# SAMA7D65D4GN8 register map
Vendor: Microchip Technology; Series: SAMA7D6; File version: 0
Registers are 32-bit, read-write, reset 0x0 unless marked. A register's access mark holds for its fields unless they carry their own. Offsets are from the block's base; [hi:lo] are bit positions; lines under a group give offsets from that group; {n}, {i} and the like mark numbered series; 'fields as' and 'values as' point back to an identical list.

## LCDC — LCD Controller
Base 0xE1400000
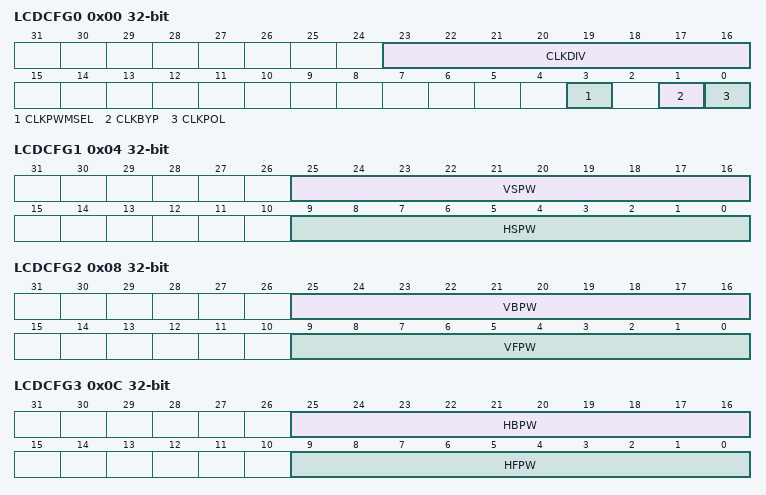
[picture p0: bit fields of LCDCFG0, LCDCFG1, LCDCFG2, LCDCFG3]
0x00 LCDCFG0 — Configuration Register 0
  [23:16] CLKDIV — LCDC Clock Divider
  [3] CLKPWMSEL — LCDC PWM Clock Source Selection
    0=The slow clock is selected and feeds the PWM module; 1=The peripheral clock (MCK) is selected and feeds the PWM module
  [1] CLKBYP — LCDC Pixel Clock Divider Bypass
    0=Pixel clock divider is not bypassed. LCDC_PCK is defined with CLKDIV parameter.; 1=Pixel clock divider is bypassed. LCDC_PCK = GCLK clock
  [0] CLKPOL — LCDC Clock Polarity
    0=Data/Control signals are launched on the rising edge of the pixel clock; 1=Data/Control signals are launched on the falling edge of the pixel clock
0x04 LCDCFG1 — Configuration Register 1
  [25:16] VSPW — Vertical Synchronization Pulse Width
  [9:0] HSPW — Horizontal Synchronization Pulse Width
0x08 LCDCFG2 — Configuration Register 2
  [25:16] VBPW — Vertical Back Porch Width
  [9:0] VFPW — Vertical Front Porch Width
0x0C LCDCFG3 — Configuration Register 3
  [25:16] HBPW — Horizontal Back Porch Width
  [9:0] HFPW — Horizontal Front Porch Width
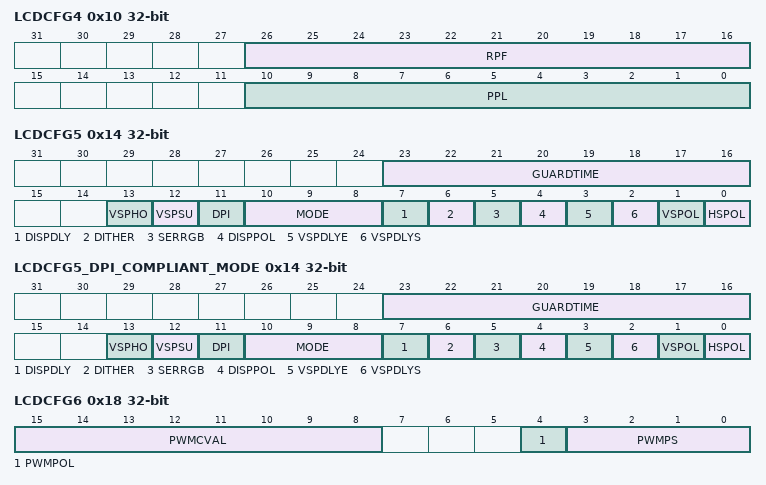
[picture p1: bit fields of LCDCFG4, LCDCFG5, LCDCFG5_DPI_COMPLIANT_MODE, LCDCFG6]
0x10 LCDCFG4 — Configuration Register 4
  [26:16] RPF — Number of Active Row Per Frame
  [10:0] PPL — Number of Pixels Per Line
0x14 LCDCFG5 — Configuration Register 5
  [23:16] GUARDTIME — LCD Display Guard Time
  [13] VSPHO — LCDC Vertical Synchronization Pulse Hold Configuration
    0=The vertical synchronization pulse is asserted synchronously with horizontal pulse edge; 1=The vertical synchronization pulse is held active one pixel clock cycle after the horizontal pulse
  [12] VSPSU — LCDC Vertical Synchronization Pulse Setup Configuration
    0=The vertical synchronization pulse is asserted synchronously with horizontal pulse edge; 1=The vertical synchronization pulse is asserted one pixel clock cycle before the horizontal pulse
  [11] DPI — Display Pixel Interface Compatible Mode
    0=Legacy pixel mapping; 1=Activates the DPI compliant pixel stream. See field MODE: LCDC Output Mode
  [10:8] MODE — LCDC Output Mode
    0=OUTPUT_12BPP (LCD Output mode is set to 12 bits per pixel); 1=OUTPUT_16BPP (LCD Output mode is set to 16 bits per pixel); 2=OUTPUT_18BPP (LCD Output mode is set to 18 bits per pixel); 3=OUTPUT_24BPP (LCD Output mode is set to 24 bits per pixel)
  [7] DISPDLY — LCDC Display Power Signal Synchronization
    0=The LCDC_DISP signal is asserted synchronously with the second active edge of the horizontal pulse; 1=The LCDC_DISP signal is asserted asynchronously with both edges of the horizontal pulse
  [6] DITHER — LCDC Dithering
    0=Dithering logical unit is disabled; 1=Dithering logical unit is activated
  [5] SERRGB — Serial RGB Mode (See Figure 7-29)
    0=Serial RGB mode is disabled; 1=Serial RGB mode is enabled
  [4] DISPPOL — Display Signal Polarity
    0=Active high; 1=Active low
  [3] VSPDLYE — Vertical Synchronization Pulse End
    0=The second active edge of the vertical synchronization pulse is synchronous with the second edge of the horizontal pulse; 1=The second active edge of the vertical synchronization pulse is synchronous with the first edge of the horizontal pulse
  [2] VSPDLYS — Vertical Synchronization Pulse Start
    0=The first active edge of the vertical synchronization pulse is synchronous with the second edge of the horizontal pulse; 1=The first active edge of the vertical synchronization pulse is synchronous with the first edge of the horizontal pulse
  [1] VSPOL — Vertical Synchronization Pulse Polarity
    0=Active high; 1=Active low
  [0] HSPOL — Horizontal Synchronization Pulse Polarity
    0=Active high; 1=Active low
0x14 LCDCFG5_DPI_COMPLIANT_MODE (alternate view of LCDCFG5) — Configuration Register 5
  [23:16] GUARDTIME — LCD Display Guard Time
  [13] VSPHO — LCDC Vertical Synchronization Pulse Hold Configuration
    values as LCDCFG5.VSPHO
  [12] VSPSU — LCDC Vertical Synchronization Pulse Setup Configuration
    values as LCDCFG5.VSPSU
  [11] DPI — Display Pixel Interface Compatible Mode
    values as LCDCFG5.DPI
  [10:8] MODE — LCDC Output Mode
    0=OUTPUT_DPI_16BPPCFG1 (LCD Output mode is set to 16 bits per pixel Configuration 1); 1=OUTPUT_DPI_16BPPCFG2 (LCD Output mode is set to 16 bits per pixel Configuration 2); 2=OUTPUT_DPI_16BPPCFG3 (LCD Output mode is set to 16 bits per pixel Configuration 3); 3=OUTPUT_DPI_18BPPCFG1 (LCD Output mode is set to 18 bits per pixel Configuration 1); 4=OUTPUT_DPI_18BPPCFG2 (LCD Output mode is set to 18 bits per pixel Configuration 2); 5=OUTPUT_DPI_24BPP (LCD Output mode is set to 24 bits per pixel)
  [7] DISPDLY — LCDC Display Power Signal Synchronization
    values as LCDCFG5.DISPDLY
  [6] DITHER — LCDC Dithering
    values as LCDCFG5.DITHER
  [5] SERRGB — Serial RGB Mode (See Figure 7-29)
    0=Serial RGB mode is disabled; 1=Serial RGB mode is enabled
  [4] DISPPOL — Display Signal Polarity
    0=Active high; 1=Active low
  [3] VSPDLYE — Vertical Synchronization Pulse End
    values as LCDCFG5.VSPDLYE
  [2] VSPDLYS — Vertical Synchronization Pulse Start
    values as LCDCFG5.VSPDLYS
  [1] VSPOL — Vertical Synchronization Pulse Polarity
    0=Active high; 1=Active low
  [0] HSPOL — Horizontal Synchronization Pulse Polarity
    0=Active high; 1=Active low
0x18 LCDCFG6 — Configuration Register 6
  [15:8] PWMCVAL — LCDC PWM Compare Value
  [4] PWMPOL — LCDC PWM Signal Polarity
    0=The output pulses are low level; 1=The output pulses are high level (the output is high whenever the value in the counter is less than the value PWMCVAL)
  [3:0] PWMPS — PWM Clock Prescaler
    0=DIV_1 (The counter advances at a rate of fCOUNTER = fPWM_SELECTED_CLOCK); 1=DIV_2 (The counter advances at a rate of fCOUNTER = fPWM_SELECTED_CLOCK/2); 2=DIV_4 (The counter advances at a rate of fCOUNTER = fPWM_SELECTED_CLOCK/4); 3=DIV_8 (The counter advances at a rate of fCOUNTER = fPWM_SELECTED_CLOCK/8); 4=DIV_16 (The counter advances at a rate of fCOUNTER = fPWM_SELECTED_CLOCK/16); 5=DIV_32 (The counter advances at a of rate fCOUNTER = fPWM_SELECTED_CLOCK/32); 6=DIV_64 (The counter advances at a of rate fCOUNTER = fPWM_SELECTED_CLOCK/64); 7=DIV_128 (The counter advances at a of rate fCOUNTER = fPWM_SELECTED_CLOCK/128); 8=DIV_256 (The counter advances at a of rate fCOUNTER = fPWM_SELECTED_CLOCK/256); 9=DIV_512 (The counter advances at a of rate fCOUNTER = fPWM_SELECTED_CLOCK/512); 10=DIV_1024 (The counter advances at a of rate fCOUNTER = fPWM_SELECTED_CLOCK/1024); 11=DIV_2048 (The counter advances at a of rate fCOUNTER = fPWM_SELECTED_CLOCK/2048); 12=DIV_4096 (The counter advances at a of rate fCOUNTER = fPWM_SELECTED_CLOCK/4096); 13=DIV_8192 (The counter advances at a of rate fCOUNTER = fPWM_SELECTED_CLOCK/8192); 14=DIV_16384 (The counter advances at a of rate fCOUNTER = fPWM_SELECTED_CLOCK/16384); 15=DIV_32768 (The counter advances at a of rate fCOUNTER = fPWM_SELECTED_CLOCK/32768)
0x1C LCDCFG7 — Configuration Register 7
  [10:0] ROW — Row Identifier For Row Interrupt Signal
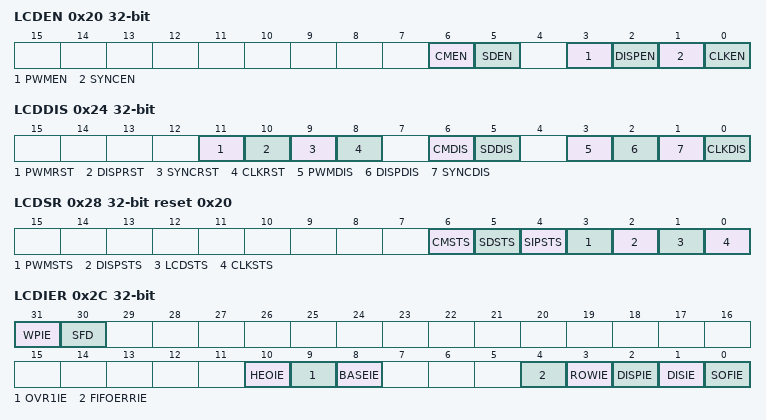
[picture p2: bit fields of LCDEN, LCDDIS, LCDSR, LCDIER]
0x20 LCDEN wo — Enable Register
  [6] CMEN — Color Mode Signal Enable
    0=No effect; 1=Sets the color mode signal (lcd_cm) to one. If a rising edge is generated, signals the MIPI DSI host to send a 'Color Mode On' command to the LCD screen when the MIPI output interface is selected.
  [5] SDEN — Shutdown Signal Enable
    0=No effect; 1=Sets the shutdown signal (lcd_sd) to zero (turns on the display)
  [3] PWMEN — LCDC Pulse Width Modulation Enable
    0=No effect; 1=PWM is enabled
  [2] DISPEN — LCDC DISP Signal Enable
    0=No effect; 1=LCDC_DISP signal is generated
  [1] SYNCEN — LCDC Horizontal and Vertical Synchronization Enable
    0=No effect; 1=Both horizontal and vertical synchronization (LCD_VSYNC and LCD_HSYNC) signals are generated
  [0] CLKEN — LCDC Pixel Clock Enable
    0=No effect; 1=Pixel clock logical unit is activated
0x24 LCDDIS wo — Disable Register
  [11] PWMRST — LCDC PWM Reset
    0=No effect; 1=Resets the PWM module immediately. The duty cycle may be violated.
  [10] DISPRST — LCDC DISP Signal Reset
    0=No effect; 1=Resets the DISP signal immediately
  [9] SYNCRST — LCDC Horizontal and Vertical Synchronization Reset
    0=No effect; 1=Resets the timing engine immediately. The horizontal and vertical pulse widths are both violated.
  [8] CLKRST — LCDC Clock Reset
    0=No effect; 1=Resets the pixel clock generator module immediately. The pixel clock duty cycle may be violated.
  [6] CMDIS — Color Mode Signal Disable
    0=No effect; 1=Sets the color mode signa (lcd_cm) to zero. If a falling edge is generated, signals the MIPI DSI host to send a 'Color Mode Off' command to the LCD screen when the MIPI output interface is selected).
  [5] SDDIS — Shutdown Signal Disable
    0=No effect; 1=Sets the shutdown signal (lcd_sd) to one (turns off the display)
  [3] PWMDIS — LCDC Pulse Width Modulation Disable
    0=No effect; 1=Disables the pulse width modulation signal after the end of the frame
  [2] DISPDIS — LCDC DISP Signal Disable
    0=No effect; 1=Disables the DISP signal after the end of the frame
  [1] SYNCDIS — LCDC Horizontal and Vertical Synchronization Disable
    0=No effect; 1=Disables the synchronization signals after the end of the frame
  [0] CLKDIS — LCDC Pixel Clock Disable
    0=No effect; 1=Disables the pixel clock after the end of the frame
0x28 LCDSR ro reset 0x20 — Status Register
  [6] CMSTS — Color Mode Signal Status
    0=Color mode signal output is zero; 1=Color mode signal output is one
  [5] SDSTS — Shutdown Signal Status
    0=Shutdown signal output is zero; 1=Shutdown signal output is one
  [4] SIPSTS — Synchronization In Progress
    0=Clock domain synchronization is terminated; 1=Synchronization is in progress. Access to the registers LCDC_LCDCCFG[0..7], LCDC_LCDEN and LCDC_LCDDIS has no effect.
  [3] PWMSTS — LCDC PWM Signal Status
    0=PWM is disabled; 1=PWM signal is activated
  [2] DISPSTS — LCDC DISP Signal Status
    0=DISP is disabled; 1=DISP signal is activated
  [1] LCDSTS — LCDC Synchronization Status
    0=Timing engine is disabled; 1=Timing engine is running
  [0] CLKSTS — Clock Status
    0=Pixel clock is disabled; 1=Pixel clock is running
0x2C LCDIER wo — Interrupt Enable Register
  [31] WPIE — Write Protection Interrupt Enable
  [30] SFD — Safety Fault Detection Interrupt Enable
  [10] HEOIE — High-End Overlay Interrupt Enable
  [9] OVR1IE — Overlay 1 Interrupt Enable
  [8] BASEIE — Base Layer Interrupt Enable
  [4] FIFOERRIE — Output FIFO Error Interrupt Enable
  [3] ROWIE — Row Interrupt Enable
  [2] DISPIE — Power-up/Power-down Sequence Terminated Interrupt Enable
  [1] DISIE — LCD Disable Interrupt Enable
  [0] SOFIE — Start of Frame Interrupt Enable
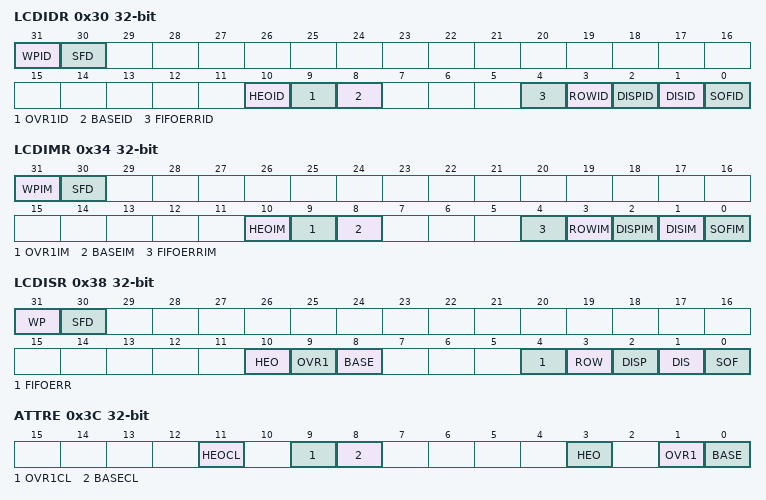
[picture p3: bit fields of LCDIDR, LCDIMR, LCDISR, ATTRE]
0x30 LCDIDR wo — Interrupt Disable Register
  [31] WPID — Write Protection Interrupt Disable
  [30] SFD — Safety Fault Detection Interrupt Disable
  [10] HEOID — High-End Overlay Interrupt Disable
  [9] OVR1ID — Overlay 1 Interrupt Disable
  [8] BASEID — Base Layer Interrupt Disable
  [4] FIFOERRID — Output FIFO Error Interrupt Disable
  [3] ROWID — Row Interrupt Disable
  [2] DISPID — Power-up/Power-down Sequence Terminated Interrupt Disable
  [1] DISID — LCD Disable Interrupt Disable
  [0] SOFID — Start of Frame Interrupt Disable
0x34 LCDIMR ro — Interrupt Mask Register
  [31] WPIM — Write Protection Interrupt Mask
  [30] SFD — Safety Fault Detection Interrupt Mask
  [10] HEOIM — High-End Overlay Interrupt Mask
  [9] OVR1IM — Overlay 1 Interrupt Mask
  [8] BASEIM — Base Layer Interrupt Mask
  [4] FIFOERRIM — Output FIFO Error Interrupt Mask
  [3] ROWIM — Row Interrupt Mask
  [2] DISPIM — Power-up/Power-down Sequence Terminated Interrupt Mask
  [1] DISIM — LCD Disable Interrupt Mask
  [0] SOFIM — Start of Frame Interrupt Mask
0x38 LCDISR ro — Interrupt Status Register
  [31] WP — Write Protection Interrupt Status
    0=No Write Protection interrupt detected since last read of LCDC_LCDISR; 1=Indicates that Write Protection error has been detected. This flag is reset after a read operation.
  [30] SFD — Safety Fault Detection Interrupt Status
    0=No detection since last read of LCDC_LCDISR; 1=Indicates that a fault has been detected in the fault detection mechanism. This flag is reset after a read operation.
  [10] HEO — High-End Overlay Raw Interrupt Status
    0=No High-End layer interrupt detected since last read of LCDC_HEOISR; 1=Indicates that a High-End layer interrupt is pending. This flag is reset as soon as the LCDC_HEOISR is read.
  [9] OVR1 — Overlay 1 Raw Interrupt Status
    0=No Overlay 1 layer interrupt detected since last read of LCDC_OVR1ISR; 1=Indicates that an Overlay 1 layer interrupt is pending. This flag is reset as soon as the LCDC_OVR1ISR is read.
  [8] BASE — Base Layer Raw Interrupt Status
    0=No base layer interrupt detected since last read of LCDC_BASEISR; 1=Indicates that a base layer interrupt is pending. This flag is reset as soon as the LCDC_BASEISR is read.
  [4] FIFOERR — Output FIFO Error
    0=No underflow has occurred in the output FIFO since last read of LCDC_LCDISR; 1=Indicates that an underflow has occurred in the output FIFO. This flag is reset after a read operation.
  [3] ROW — Row Interrupt Status
    0=No detection since last read of the LCDC_LCDCISR; 1=Indicates that a row event has been detected. This flag is reset after a read operation.
  [2] DISP — Power-up/Power-down Sequence Terminated Interrupt Status
    0=Power-up sequence or power-down sequence has not yet terminated; 1=Indicates the power-up sequence or power-down sequence has terminated. This flag is reset after a read operation.
  [1] DIS — LCD Disable Interrupt Status
    0=Horizontal and vertical timing generator has not yet been disabled; 1=Indicates that the horizontal and vertical timing generator has been disabled. This flag is reset after a read operation.
  [0] SOF — Start of Frame Interrupt Status
    0=No detection since last read of LCDC_LCDISR; 1=Indicates that a start of frame event has been detected. This flag is reset after a read operation.
0x3C ATTRE wo — Attribute Enable Register
  [11] HEOCL — High-End Overlay Update Color LUT
    0=No effect; 1=DMA update request for the HEO layer CLUT content
  [9] OVR1CL — Overlay 1 Update Color LUT
    0=No effect; 1=DMA update request for the OVR1 layer CLUT content
  [8] BASECL — Base Layer Update Color LUT
    0=No effect; 1=DMA update request for the base layer CLUT content
  [3] HEO — High-End Overlay Update Attribute
    0=No effect; 1=Updates the HEO window attribute
  [1] OVR1 — Overlay 1 Update Attribute
    0=No effect; 1=Updates the OVR1 window attribute
  [0] BASE — Base Layer Update Attribute
    0=No effect; 1=Updates the base window attributes
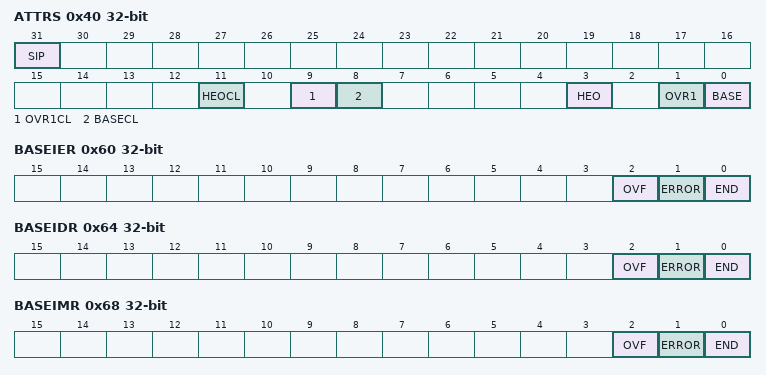
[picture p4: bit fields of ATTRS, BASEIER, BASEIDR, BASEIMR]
0x40 ATTRS ro — Attribute Status Register
  [31] SIP — Synchronization In Progress
    0=Clock domain synchronization is terminated; 1=Synchronization is in progress. Access to LCDC_ATTRE has no effect.
  [11] HEOCL — High-End Overlay Color Table Status
    0=No effect; 1=Indicates that an update request is pending for the High-end Overlay CLUT
  [9] OVR1CL — Overlay 1 Color Table Status
    0=No effect; 1=Indicates that an update request is pending for the Overlay 1 CLUT
  [8] BASECL — Base Layer Color Table Status
    0=No effect; 1=Indicates that an update request is pending for the base CLUT
  [3] HEO — High-End Overlay Update Status
    0=No effect; 1=Indicates that an update request is pending for High-end Overlay
  [1] OVR1 — Overlay 1 Update Status
    0=No effect; 1=Indicates that an update request is pending for the Overlay 1 layer
  [0] BASE — Base Layer Update Status
    0=No effect; 1=Indicates that an update request is pending for the base layer
0x60 BASEIER wo — Base Layer Interrupt Enable Register
  [2] OVF — Overflow Interrupt Enable
  [1] ERROR — Transfer Error Detected Interrupt Enable
  [0] END — End of Frame DMA Transfer Interrupt Enable
0x64 BASEIDR wo — Base Layer Interrupt Disable Register
  [2] OVF — Overflow Interrupt Disable
  [1] ERROR — Transfer Error Interrupt Disable
  [0] END — End of Frame DMA Transfer Interrupt Disable
0x68 BASEIMR ro — Base Layer Interrupt Mask Register
  [2] OVF — Overflow Interrupt Mask
  [1] ERROR — Transfer Error Interrupt Mask
  [0] END — End of Frame DMA Transfer Interrupt Mask
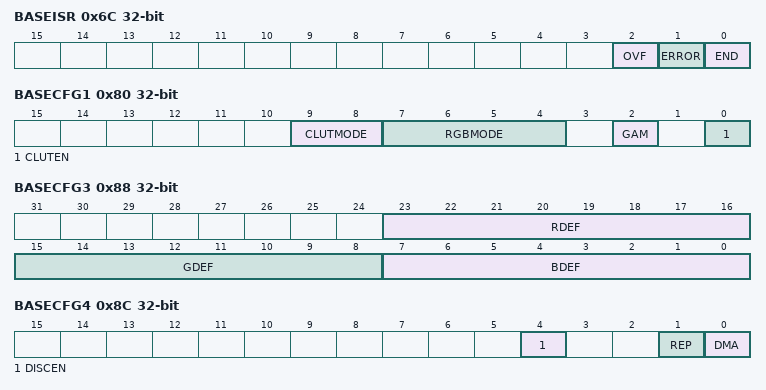
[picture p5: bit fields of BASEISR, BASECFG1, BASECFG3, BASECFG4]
0x6C BASEISR ro — Base Layer Interrupt Status Register
  [2] OVF — Overflow Detected
    0=No overflow occurred since last read of LCDC_BASEISR; 1=An overflow occurred, at least one DMA transfer is still running at the End Of Frame. This flag is reset after a read operation.
  [1] ERROR — Transfer Error Detected
    0=No system bus error has been detected since the last read of LCDC_BASEISR; 1=A system bus error has been detected. This flag is reset after a read operation.
  [0] END — End of Frame DMA Transfer
    0=No end of frame DMA transfer has been detected since last read of LCDC_BASEISR; 1=End of transfer has been detected. This flag is reset after a read operation.
0x70 BASEEN — Base Layer Enable Register
  [0] ENABLE — Base Layer Enable
    0=The layer is disabled; 1=The layer is enabled
0x74 BASECLA — Base Layer Color Table Address Register
  [31:3] CLA — Base Layer CLUT Address
0x78 BASEFBA — Base Layer Frame Buffer Address Register
  [31:2] FBA — Frame Buffer Address
0x7C BASECFG0 — Base Layer Configuration Register 0
  [6:4] BLEN — System Bus Burst Length
    0=INCR1 (System bus access is started as soon as there is enough space in the FIFO to store one data.); 1=INCR4 (System bus access is started as soon as there is enough space in the FIFO to store a total amount of 4 data. A system bus INCR4 Burst is used by default. INCR1 is used for bursts less than 4.); 2=INCR8 (System bus access is started as soon as there is enough space in the FIFO to store a total amount of 8 data. A system bus INCR8 Burst is used by default. INCR4 bursts are used for bursts of 4 beats.INCR1 is used for bursts less than 4.); 3=INCR16 (System bus access is started as soon as there is enough space in the FIFO to store a total amount of 16 data. A system bus INCR16 Burst is used by default. INCR8 and INCR4 bursts are respectively used for bursts of 8 and 4 beats.INCR1 is used for bursts less than 4.); 4=INCR32 (System bus access is started as soon as there is enough space in the FIFO to store a total amount of 32 data. A system bus INCR32 Burst is used by default. INCR16, INCR8 and INCR4 bursts are respectively used for bursts of 16, 8 and 4 beats. INCR1 is used for bursts less than 4.)
0x80 BASECFG1 — Base Layer Configuration Register 1
  [9:8] CLUTMODE — CLUT Mode Input Selection
    0=CLUT_1BPP (CLUT mode set to 1 bit per pixel); 1=CLUT_2BPP (CLUT mode set to 2 bits per pixel); 2=CLUT_4BPP (CLUT mode set to 4 bits per pixel); 3=CLUT_8BPP (CLUT mode set to 8 bits per pixel)
  [7:4] RGBMODE — RGB Mode Input Selection
    0=12BPP_RGB_444; 1=16BPP_ARGB_4444; 2=16BPP_RGBA_4444; 3=16BPP_RGB_565; 4=16BPP_ARGB_1555; 5=18BPP_RGB_666; 6=18BPP_RGB_666PACKED; 7=19BPP_ARGB_1666; 8=19BPP_ARGB_PACKED (19 bpp ARGB 1666 PACKED); 9=24BPP_RGB_888; 10=24BPP_RGB_888_PACKED; 11=25BPP_ARGB_1888; 12=32BPP_ARGB_8888; 13=32BPP_RGBA_8888
  [2] GAM — Gamma Correction
    0=Gamma correction is disabled; 1=Gamma correction is activated
  [0] CLUTEN — CLUT Mode Enable
    0=RGB mode is selected; 1=CLUT mode is selected
0x84 BASECFG2 — Base Layer Configuration Register 2
  [31:0] XSTRIDE — Horizontal Stride
0x88 BASECFG3 — Base Layer Configuration Register 3
  [23:16] RDEF — Red Default
  [15:8] GDEF — Green Default
  [7:0] BDEF — Blue Default
0x8C BASECFG4 — Base Layer Configuration Register 4
  [4] DISCEN — Discard Area Enable
    0=The whole frame is retrieved from memory; 1=The DMA channel discards the area located at screen coordinates {DISCXPOS, DISCYPOS}
  [1] REP — Use Replication Logic to Expand RGB Color to 24 Bits
    0=When the selected pixel depth is less than 24 bpp, the pixel is shifted and LSBs are set to 0; 1=When the selected pixel depth is less than 24 bpp, the pixel is shifted and the LSB replicates the MSB
  [0] DMA — Use DMA Data Path
    0=The default color is used on the base layer; 1=The DMA channel retrieves the pixel stream from the memory
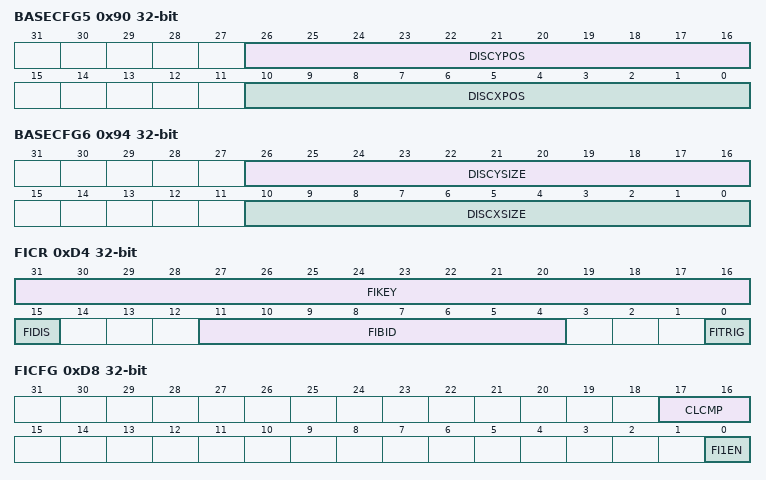
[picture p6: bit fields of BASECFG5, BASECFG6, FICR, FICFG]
0x90 BASECFG5 — Base Layer Configuration Register 5
  [26:16] DISCYPOS — Discard Area Vertical Coordinate
  [10:0] DISCXPOS — Discard Area Horizontal Coordinate
0x94 BASECFG6 — Base Layer Configuration Register 6
  [26:16] DISCYSIZE — Discard Area Vertical Size
  [10:0] DISCXSIZE — Discard Area Horizontal Size
0xD4 FICR — Fault Injection Control Register
  [31:16] FIKEY — Write Protection Key Password
    0x4C43=PASSWD (Writing any other value in this field aborts the write operation of the FITRIG, FIBID bits. Always reads as 0.)
  [15] FIDIS — Fault Injection Control Register Disable
    0=NO_EFFECT; 1=ACTIVE (Locks the write access to LCDC_FICR until the next system reset.)
  [11:4] FIBID — Fault Injection Block Index
  [0] FITRIG — Fault Injection Trigger
    0=No Fault is injected; 1=Fault is injected once
0xD8 FICFG — Fault Injection Configuration Register
  [17:16] CLCMP — CLUT Ram Component Index
    0=Blue Component; 1=Green Component; 2=Red Component; 3=Alpha Component
  [0] FI1EN — Fault Injection 1 Enable
    0=First fault injection is disabled; 1=First fault injection is enabled
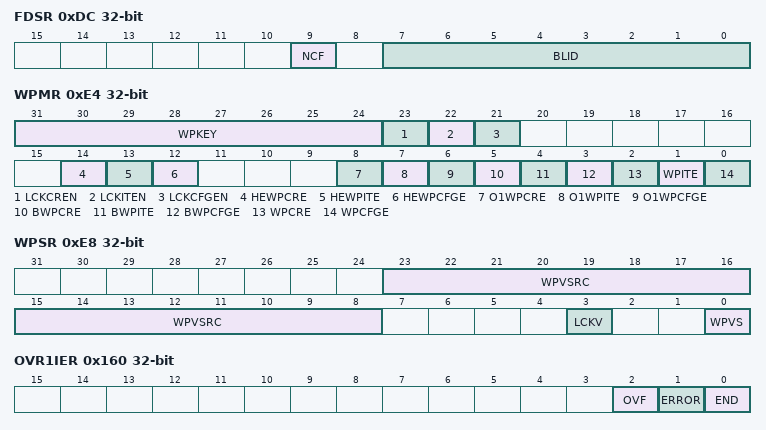
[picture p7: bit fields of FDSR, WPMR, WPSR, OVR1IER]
0xDC FDSR ro — Fault Detection Status Register
  [9] NCF — Non-Corrected Fault Status
    0=No non-correctable fault has been detected since the last read of LCDC_FDSR; 1=A non-correctable fault has been detected. This flag is reset after a read operation.
  [7:0] BLID — Block Index
0xE4 WPMR — Write Protection Mode Register
  [31:24] WPKEY — Write Protection Key Password
    88=PASSWD (Writing any other value in this field aborts the write operation of the WPCFGE, WPITE, WPCRE bits. Always reads as 0.)
  [23] LCKCREN — Write Protection Lock Enable for Control Register
    0=No effect; 1=Locks the write access to the WPCRE bit until the next system reset. WPCRE must be set in the same access to per-form the action.
  [22] LCKITEN — Write Protection Lock Enable for Interrupt Register
    0=No effect; 1=Locks the write access to the WPITE bit until the next system reset. WPITE must be set in the same access to per-form the action.
  [21] LCKCFGEN — Write Protection Lock Enable for Configuration Register
    0=No effect; 1=Locks the write access to the WPCFEN bit until the next system reset. WPCFEN must be set in the same access to per-form the action.
  [14] HEWPCRE — High-End Overlay Write Protection Control Registers Enable
    0=Disables the write protection of High-End Overlay Control registers if WPKEY corresponds to 0x58 ('X' in ASCII); 1=Enables the write protection of High-End Overlay Control registers if WPKEY corresponds to 0x58 ('X' in ASCII)
  [13] HEWPITE — High-End Overlay Write Protection Interrupt Registers Enable
    0=Disables the write protection of High-End Overlay Interrupt Enable/Disable registers if WPKEY corresponds to 0x58 ('X' in ASCII); 1=Enables the write protection of High-End Overlay Interrupt Enable/Disable registers if WPKEY corresponds to 0x58 ('X' in ASCII)
  [12] HEWPCFGE — High-End Overlay Write Protection Configuration Registers Enable
    0=Disables the write protection of High-End Overlay Configuration registers if WPKEY corresponds to 0x58 ('X' in ASCII); 1=Enables the write protection of High-End Overlay Configuration registers if WPKEY corresponds to 0x58 ('X' in ASCII)
  [8] O1WPCRE — Overlay 1 Write Protection Control Registers Enable
    0=Disables the write protection of Overlay 1 Control registers if WPKEY corresponds to 0x58 ('X' in ASCII); 1=Enables the write protection of Overlay 1 Control registers if WPKEY corresponds to 0x58 ('X' in ASCII)
  [7] O1WPITE — Overlay 1 Write Protection Interrupt Registers Enable
    0=Disables the write protection of Overlay 1 Interrupt Enable/Disable registers if WPKEY corresponds to 0x58 ('X' in ASCII); 1=Enables the write protection of Overlay 1 Interrupt Enable/Disable registers if WPKEY corresponds to 0x58 ('X' in ASCII)
  [6] O1WPCFGE — Overlay 1 Write Protection Configuration Registers Enable
    0=Disables the write protection of Overlay 1 Configuration registers if WPKEY corresponds to 0x58 ('X' in ASCII); 1=Enables the write protection of Overlay 1 Configuration registers if WPKEY corresponds to 0x58 ('X' in ASCII)
  [5] BWPCRE — Base Layer Write Protection Control Registers Enable
    0=Disables the write protection of base layer Control registers if WPKEY corresponds to 0x58 ('X' in ASCII); 1=Enables the write protection of base layer Control registers if WPKEY corresponds to 0x58 ('X' in ASCII)
  [4] BWPITE — Base Layer Write Protection Interrupt Registers Enable
    0=Disables the write protection of base layer Interrupt Enable/Disable registers if WPKEY corresponds to 0x58 ('X' in ASCII); 1=Enables the write protection of base layer Interrupt Enable/Disable registers if WPKEY corresponds to 0x58 ('X' in ASCII)
  [3] BWPCFGE — Base Layer Write Protection Configuration Registers Enable
    0=Disables the write protection of base layer Configuration registers if WPKEY corresponds to 0x58 ('X' in ASCII); 1=Enables the write protection of base layer Configuration registers if WPKEY corresponds to 0x58 ('X' in ASCII)
  [2] WPCRE — Write Protection Control Registers Enable
    0=Disables the write protection of LCDC Control registers if WPKEY corresponds to 0x58 ('X' in ASCII); 1=Enables the write protection of LCDC Control registers if WPKEY corresponds to 0x58 ('X' in ASCII)
  [1] WPITE — Write Protection Interrupt Registers Enable
    0=Disables the write protection of LCDC Interrupt Enable/Disable registers if WPKEY corresponds to 0x58 ('X' in ASCII); 1=Enables the write protection of LCDC Interrupt Enable/Disable registers if WPKEY corresponds to 0x58 ('X' in ASCII)
  [0] WPCFGE — Write Protection Configuration Registers Enable
    0=Disables the write protection of LCDC Configuration registers if WPKEY corresponds to 0x58 ('X' in ASCII); 1=Enables the write protection of LCDC Configuration registers if WPKEY corresponds to 0x58 ('X' in ASCII)
0xE8 WPSR ro — Write Protection Status Register
  [23:8] WPVSRC — Write Protection Violation Source
  [3] LCKV — Lock Violation Status
    0=No lock violation has occurred since the last read of LCDC_WPSR; 1=A lock violation related to LCDC_WPMR.LCKCFGEN, LCDC_WPMR.LCKITEN or LCDC_WPMR.LCKCREN has occurred since the last read of LCDC_WPSR
  [0] WPVS — Write Protection Violation Status
0x160 OVR1IER wo — Overlay 1 Interrupt Enable Register
  fields as BASEIER
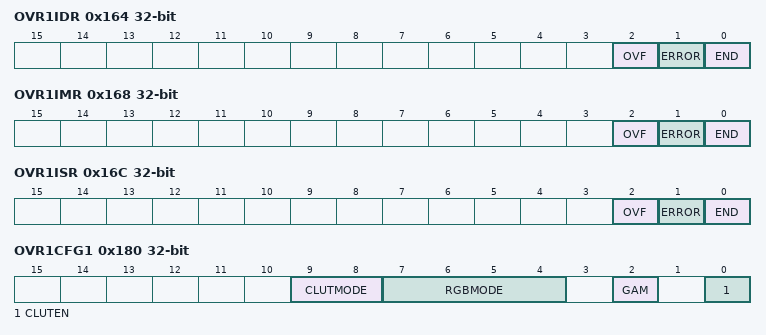
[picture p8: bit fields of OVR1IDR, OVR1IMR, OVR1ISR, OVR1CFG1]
0x164 OVR1IDR wo — Overlay 1 Interrupt Disable Register
  [2] OVF — Overflow Interrupt Disable
  [1] ERROR — Error Interrupt Disable
  [0] END — End of Frame DMA Transfer Interrupt Disable
0x168 OVR1IMR ro — Overlay 1 Interrupt Mask Register
  [2] OVF — Overflow Interrupt Mask
  [1] ERROR — Bus Error Detected Interrupt Mask
  [0] END — End of Frame DMA Transfer Interrupt Mask
0x16C OVR1ISR ro — Overlay 1 Interrupt Status Register
  [2] OVF — Overflow Detected
    0=No overflow occurred since last read of LCDC_OVR1ISR; 1=An overflow occurred, at least one DMA transfer is still running at the End Of Frame. This flag is reset after a read operation
  [1] ERROR — Bus Error Detected
    0=No system bus error has been detected since the last read of LCDC_OVR1ISR; 1=A system bus error has been detected. This flag is reset after a read operation
  [0] END — End of Frame DMA Transfer
    0=No end of transfer has been detected since last read of LCDC_OVR1ISR; 1=End of transfer has been detected. This flag is reset after a read operation.
0x170 OVR1EN — Overlay 1 Enable Register
  [0] ENABLE — Layer Enable
    0=The layer is disabled; 1=The layer is enabled
0x174 OVR1CLA — Overlay 1 Color Table Address Register
  [31:3] CLA — Overlay 1 CLUT Address
0x178 OVR1FBA — Overlay 1 Frame Buffer Address Register
  [31:0] FBA — Frame Buffer Address
0x17C OVR1CFG0 — Overlay 1 Configuration Register 0
  [6:4] BLEN — System Bus Burst Length
    0=INCR1 (System bus access is started as soon as there is enough space in the FIFO to store one data.); 1=INCR4 (System bus access is started as soon as there is enough space in the FIFO to store a total amount of 4 data. A system bus INCR4 Burst is used by default. INCR1 is used for bursts less than 4.); 2=INCR8 (System bus access is started as soon as there is enough space in the FIFO to store a total amount of 8 data. A system bus INCR8 Burst is used by default. INCR4 bursts are used for burst of 4 beats. INCR1 is used for bursts less than 4.); 3=INCR16 (System bus access is started as soon as there is enough space in the FIFO to store a total amount of 16 data. A system bus INCR16 Burst is used by default. INCR8 and INCR4 bursts are respectively used for burst of 8 and 4 beats. INCR1 is used for bursts less than 4.); 4=INCR32 (System bus access is started as soon as there is enough space in the FIFO to store a total amount of 32 data. A system bus INCR32 Burst is used by default. INCR16, INCR8 and INCR4 bursts are respectively used for burst of 16, 8 and 4 beats. INCR1 is used for bursts less than 4.)
0x180 OVR1CFG1 — Overlay 1 Configuration Register 1
  [9:8] CLUTMODE — CLUT Mode Input Selection
    values as BASECFG1.CLUTMODE
  [7:4] RGBMODE — RGB Mode Input Selection
    values as BASECFG1.RGBMODE
  [2] GAM — Gamma Correction
    0=Gamma correction is disabled; 1=Gamma correction is enabled
  [0] CLUTEN — CLUT Mode Enable
    0=RGB mode is selected; 1=CLUT mode is selected
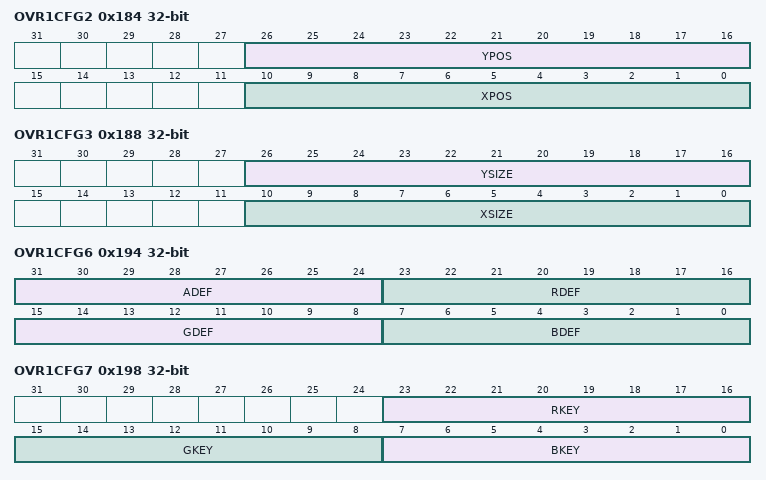
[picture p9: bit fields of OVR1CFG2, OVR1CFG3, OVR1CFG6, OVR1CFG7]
0x184 OVR1CFG2 — Overlay 1 Configuration Register 2
  [26:16] YPOS — Vertical Window Position
  [10:0] XPOS — Horizontal Window Position
0x188 OVR1CFG3 — Overlay 1 Configuration Register 3
  [26:16] YSIZE — Vertical Window Size
  [10:0] XSIZE — Horizontal Window Size
0x18C OVR1CFG4 — Overlay 1 Configuration Register 4
  [31:0] XSTRIDE — Horizontal Stride
0x190 OVR1CFG5 — Overlay 1 Configuration Register 5
  [31:0] PSTRIDE — Pixel Stride
0x194 OVR1CFG6 — Overlay 1 Configuration Register 6
  [31:24] ADEF — Alpha Default
  [23:16] RDEF — Red Default
  [15:8] GDEF — Green Default
  [7:0] BDEF — Blue Default
0x198 OVR1CFG7 — Overlay 1 Configuration Register 7
  [23:16] RKEY — Red Color Component Chroma Key
  [15:8] GKEY — Green Color Component Chroma Key
  [7:0] BKEY — Blue Color Component Chroma Key
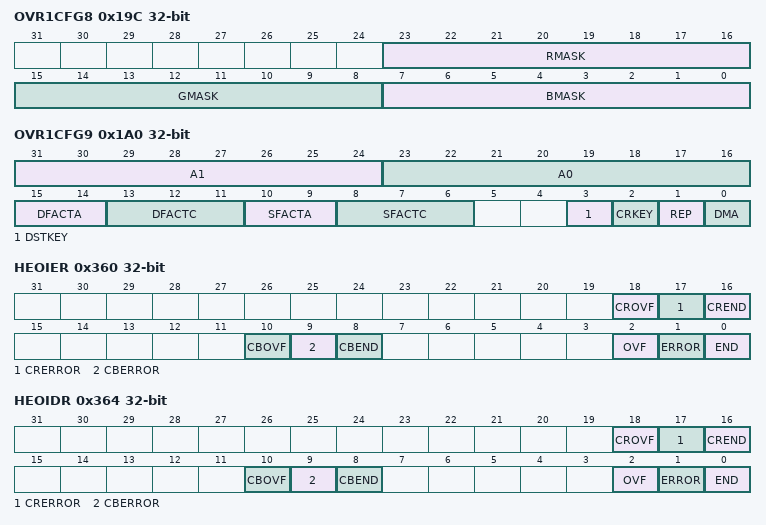
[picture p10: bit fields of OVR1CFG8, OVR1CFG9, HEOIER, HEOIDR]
0x19C OVR1CFG8 — Overlay 1 Configuration Register 8
  [23:16] RMASK — Red Color Component Chroma Key Mask
  [15:8] GMASK — Green Color Component Chroma Key Mask
  [7:0] BMASK — Blue Color Component Chroma Key Mask
0x1A0 OVR1CFG9 — Overlay 1 Configuration Register 9
  [31:24] A1 — Alpha 1 Value
  [23:16] A0 — Alpha 0 Value
  [15:14] DFACTA — Destination Factor for the Blending Equation of the Alpha Component
    0=ZERO (Sets the factor to 0.0.); 1=ONE (Sets the factor to 1.0.); 2=M_A0_MUL_AS (Computes A0 multiplied by source alpha, then sets the factor to one minus the result.); 3=A1 (Sets the factor to A1/255.)
  [13:11] DFACTC — Destination Factor for the Blending Equation of the Color Component
    0=ZERO (Sets the factor to 0.0.); 1=ONE (Sets the factor to 1.0.); 2=A0 (Sets the factor to A0/255.); 3=A1 (Sets the factor to A1/255.); 4=A0_MULT_AD (Sets the factor to A0 multiplied by Destination Alpha.); 5=M_A0_MULT_AD (Sets the factor to A0 multiplied by Destination Alpha, then sets the factor to one minus the result.); 6=M_A0_MUL_AS (Computes A0 multiplied by source alpha0, then sets the factor to one minus the result.); 7=M_A0 (Computes one minus A0, then sets the factor to one minus the result.)
  [10:9] SFACTA — Source Factor for the Blending Equation of the Alpha Component
    0=ZERO (Sets the factor to 0.0.); 1=ONE (Sets the factor to 1.0.); 2=A0 (Sets the factor to A0/255.); 3=A1 (Sets the factor to A1/255.)
  [8:6] SFACTC — Source Factor for the Blending Equation of the Color Component
    0=ONE (Sets the factor to 1.0.); 1=ZERO (Sets the factor to 0.0.); 2=A0 (Sets the factor to A0/255.); 3=A0_MULT_AD (Sets the factor to A0 multiplied by Destination Alpha.); 4=A0_MUL_AS (Sets the factor to A0 multiplied by Source Alpha.); 5=M_A0_MUL_AD (Computes A0 multiplied by Destination Alpha, then sets the factor to minus the result.)
  [3] DSTKEY — Destination Color Keying
    0=When CRKEY is enabled, color key is applied on OVR1 pixels, before the blending operation; 1=When CRKEY is enabled, color key is applied on OVR1 pixels, after the blending operation
  [2] CRKEY — Chroma Keying Enable
  [1] REP — Replication Logic
    values as BASECFG4.REP
  [0] DMA — DMA Enable
    0=The pixel for the current layer is retrieved from the default color register; 1=The pixel stream is retrieved from the memory
0x360 HEOIER wo — High-End Overlay Interrupt Enable Register
  [18] CROVF
  [17] CRERROR
  [16] CREND
  [10] CBOVF
  [9] CBERROR
  [8] CBEND
  [2] OVF — Overflow Interrupt Enable
  [1] ERROR — Bus Transfer Error Detected Interrupt Enable
  [0] END — End of Frame DMA Transfer Interrupt Enable
0x364 HEOIDR wo — High-End Overlay Interrupt Disable Register
  [18] CROVF — Overflow for Cr Chroma Plane Interrupt Disable
  [17] CRERROR — Bus Transfer Error Detected for Cr Chroma Plane Interrupt Disable
  [16] CREND — End of Frame DMA Transfer for Cr Chroma Plane Interrupt Disable
  [10] CBOVF — Overflow for Cb or CbCr Chroma Plane Interrupt Disable
  [9] CBERROR — Bus Transfer Error Detected for Cb or CbCr Chroma Plane Interrupt Disable
  [8] CBEND — End of Frame DMA Transfer for Cb or CbCr Chroma Plane Interrupt Disable
  [2] OVF — Overflow Interrupt Disable
  [1] ERROR — Bus Transfer Error Detected Interrupt Disable
  [0] END — End of Frame DMA Transfer Interrupt Disable
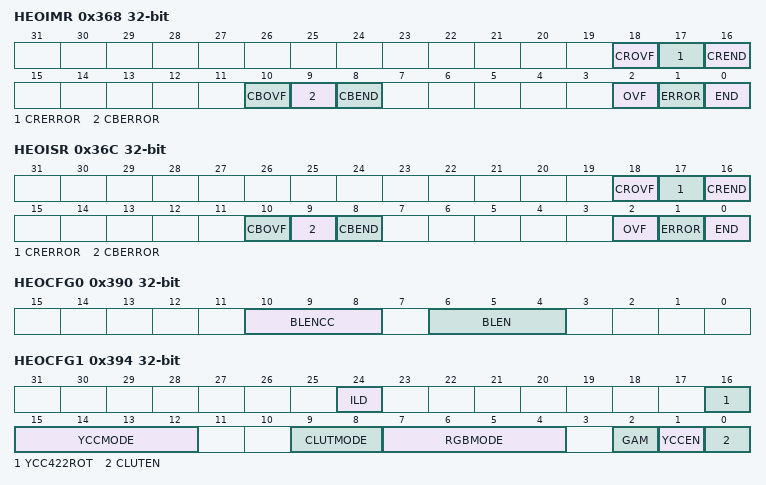
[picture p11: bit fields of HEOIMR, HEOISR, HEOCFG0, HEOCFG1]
0x368 HEOIMR ro — High-End Overlay Interrupt Mask Register
  [18] CROVF — Overflow for Cr Chroma Plane Interrupt Mask
  [17] CRERROR — Bus Transfer Error Detected for Cr Chroma Plane Interrupt Mask
  [16] CREND — End of Frame DMA Transfer for Cr Chroma Plane Interrupt Mask
  [10] CBOVF — Overflow for Cb or CbCr Chroma Plane Interrupt Mask
  [9] CBERROR — Bus Transfer Error Detected for Cb or CbCr Chroma Plane Interrupt Mask
  [8] CBEND — End of Frame DMA Transfer for Cb or CbCr Chroma Plane Interrupt Mask
  [2] OVF — Overflow Interrupt Mask
  [1] ERROR — Bus Transfer Error Detected Interrupt Mask
  [0] END — End of Frame DMA Transfer Interrupt Mask
0x36C HEOISR ro — High-End Overlay Interrupt Status Register
  [18] CROVF — Overflow Detected for Cr plane
    0=No overflow occurred since last read of LCDC_HEOISR; 1=An overflow occurred, at least one DMA transfer is still running at the End Of Frame. This flag is reset after a read operation.
  [17] CRERROR — Bus Transfer Error detected for Cr plane
    0=No system bus error has been detected since the last read of LCDC_HEOISR; 1=A system bus error has been detected. This flag is reset after a read operation.
  [16] CREND — End of Frame DMA Transfer for Cr plane
    0=No end of transfer has been detected since last read of LCDC_HEOISR; 1=End of transfer has been detected. This flag is reset after a read operation.
  [10] CBOVF — Overflow Detected for Cb or CbCr plane
    values as CROVF
  [9] CBERROR — Bus Transfer Error Detected for Cb or CbCr plane
    values as CRERROR
  [8] CBEND — End of Frame DMA Transfer for Cb or CbCr plane
    values as CREND
  [2] OVF — Overflow Detected
    0=No overflow occurred since last read of LCDC_HEOISR; 1=An overflow occurred, at least one DMA transfer is still running at the End Of Frame. This flag is reset after a read operation
  [1] ERROR — Bus Error Detected
    values as CRERROR
  [0] END — End of Frame DMA Transfer
    values as CREND
0x370 HEOEN — High-End Overlay Enable Register
  [0] ENABLE — Overlay Enable
    0=The layer is disabled; 1=The layer is enabled
0x374 HEOCLA — High-End Overlay Table Address Register
  [31:3] CLA — High-End Overlay CLUT Address
{0x378+0xC*i} LCDC_HEO[{i}] (i=0..1) group
  0x00 HEOYFBA — High-End Overlay Y Frame Buffer x Addr
    [31:0] FBA — Frame Buffer Address
  0x04 HEOCBFBA — High-End Overlay Cb Frame Buffer x Addr
    [31:0] CBFBA — Cb or CbCr Plane Frame Buffer Address
  0x08 HEOCRFBA — High-End Overlay Cr Frame Buffer x Addr
    [31:0] CRFBA — Cr Chroma Plane Frame Buffer Address
0x390 HEOCFG0 — High-End Overlay Configuration Register 0
  [10:8] BLENCC — System Bus Burst Length for Cb-Cr Channel
    0=INCR1 (System bus access is started as soon as there is enough space in the FIFO to store one data.); 1=INCR4 (System bus access is started as soon as there is enough space in the FIFO to store a total amount of 4 data. A system bus INCR4 Burst is used by default. INCR1 is used for bursts less than 4.); 2=INCR8 (System bus access is started as soon as there is enough space in the FIFO to store a total amount of 8 data. A system bus INCR8 Burst is used by default. INCR4 bursts are used for bursts of 4 beats. INCR1 is used for bursts less than 4.); 3=INCR16 (System bus access is started as soon as there is enough space in the FIFO to store a total amount of 16 data. A system bus INCR16 Burst is used by default. INCR8 and INCR4 bursts are respectively used for bursts of 8 and 4 beats. INCR1 is used for bursts less than 4.); 4=INCR32 (System bus access is started as soon as there is enough space in the FIFO to store a total amount of 32 data. A system bus INCR32 Burst is used by default. INCR16, INCR8 and INCR4 bursts are respectively used for bursts of 16, 8 and 4 beats. INCR1 is used for bursts less than 4.)
  [6:4] BLEN — System Bus Burst Length
    values as BLENCC
0x394 HEOCFG1 — High-End Overlay Configuration Register 1
  [24] ILD
  [16] YCC422ROT
  [15:12] YCCMODE
  [9:8] CLUTMODE — CLUT Mode Input Selection
    values as BASECFG1.CLUTMODE
  [7:4] RGBMODE — RGB Mode Input Selection
    values as BASECFG1.RGBMODE
  [2] GAM — Gamma Correction
    values as OVR1CFG1.GAM
  [1] YCCEN — YCbCr Color Space Enable
    0=Color space is RGB; 1=Color space is YCbCr
  [0] CLUTEN — CLUT Mode Enable
    0=RGB mode is selected; 1=CLUT mode is selected
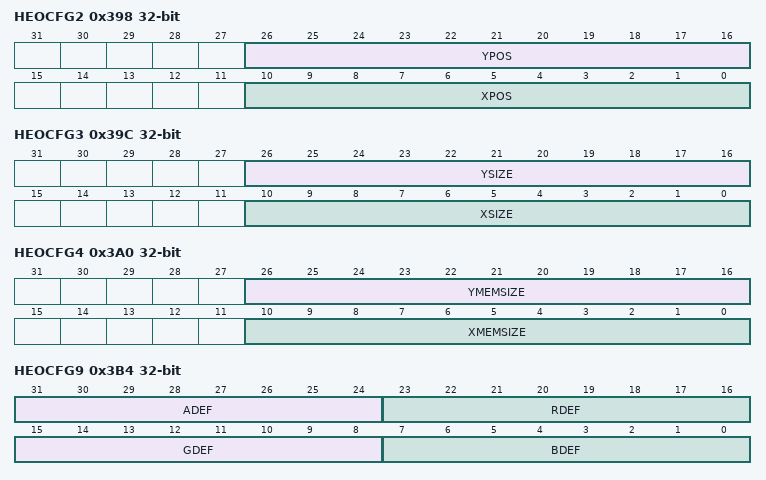
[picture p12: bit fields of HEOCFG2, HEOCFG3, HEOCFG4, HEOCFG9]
0x398 HEOCFG2 — High-End Overlay Configuration Register 2
  fields as OVR1CFG2
0x39C HEOCFG3 — High-End Overlay Configuration Register 3
  fields as OVR1CFG3
0x3A0 HEOCFG4 — High-End Overlay Configuration Register 4
  [26:16] YMEMSIZE — Vertical image Size in Memory
  [10:0] XMEMSIZE — Horizontal image Size in Memory
0x3A4 HEOCFG5 — High-End Overlay Configuration Register 5
  [31:0] XSTRIDE — Horizontal Stride
0x3A8 HEOCFG6 — High-End Overlay Configuration Register 6
  [31:0] PSTRIDE — Pixel Stride
0x3AC HEOCFG7 — High-End Overlay Configuration Register 7
  [31:0] CCXSTRIDE — CbCr Horizontal Stride
0x3B0 HEOCFG8 — High-End Overlay Configuration Register 8
  [31:0] CCPSTRIDE — CbCr Pixel Stride
0x3B4 HEOCFG9 — High-End Overlay Configuration Register 9
  fields as OVR1CFG6
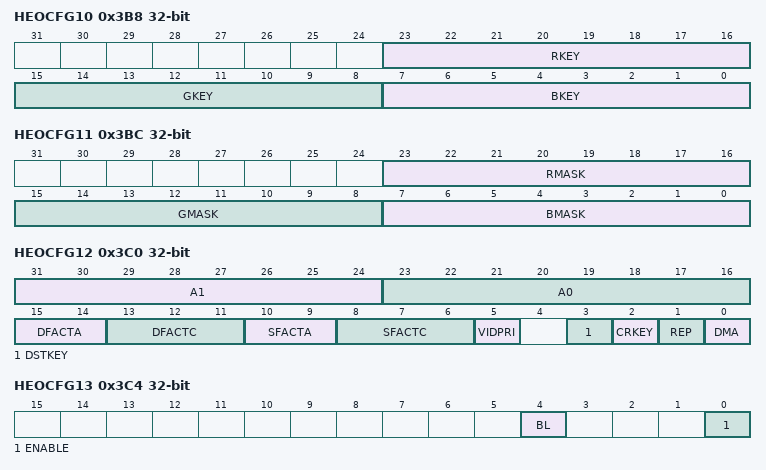
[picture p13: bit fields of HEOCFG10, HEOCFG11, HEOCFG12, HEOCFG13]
0x3B8 HEOCFG10 — High-End Overlay Configuration Register 10
  fields as OVR1CFG7
0x3BC HEOCFG11 — High-End Overlay Configuration Register 11
  fields as OVR1CFG8
0x3C0 HEOCFG12 — High-End Overlay Configuration Register 12
  [31:24] A1 — Alpha 1 Value
  [23:16] A0 — Alpha 0 Value
  [15:14] DFACTA — Destination Factor for the Blending Equation of the Alpha Component
    0=ZERO (Sets the factor to 0.0.); 1=ONE (Sets the factor to 1.0.); 2=M_A0_MUL_AS (Computes A0 multiplied by source alpha, then set the factor to one minus the result.); 3=A1 (Sets the factor to A1/255.)
  [13:11] DFACTC — Destination Factor for the Blending Equation of the Color Component
    0=ZERO (Sets the factor to 0.0.); 1=ONE (Sets the factor to 1.0.); 2=A0 (Sets the factor to A0/255.); 3=A1 (Sets the factor to A1/255.); 4=A0_MULT_AD (Sets the factor to A0 multiplied by Destination Alpha.); 5=M_A0_MULT_AD (Sets the factor to A0 multiplied by Destination Alpha, then sets the factor one minus the result.); 6=M_A0_MUL_AS (Computes A0 multiplied by source alpha0, then set the factor to one minus the result.); 7=M_A0 (Computes one minus A0, then set the factor to one minus the result.)
  [10:9] SFACTA — Source Factor for the Blending Equation of the Alpha Component
    values as OVR1CFG9.SFACTA
  [8:6] SFACTC — Source Factor for the Blending Equation of the Color Component
    values as OVR1CFG9.SFACTC
  [5] VIDPRI — Video Priority Mode
    0=HEO is located below OVR1; 1=HEO is located above OVR1
  [3] DSTKEY — Destination Color Keying
    0=When CRKEY is enabled, color key is applied on HEO pixels, before blending operation; 1=When CRKEY is enabled, color key is applied on HEO pixels, after blending operation
  [2] CRKEY — Chroma Keying
  [1] REP — Replication Logic
    values as BASECFG4.REP
  [0] DMA — DMA Enable
    values as OVR1CFG9.DMA
0x3C4 HEOCFG13 — High-End Overlay Configuration Register 13
  [4] BL — Black Level
    0=Black level offset is disabled; 1=Black level offset is enabled
  [0] ENABLE — Contrast, Brightness Hue and Saturation Enable
    0=CBHS is disabled; 1=CBHS is enabled
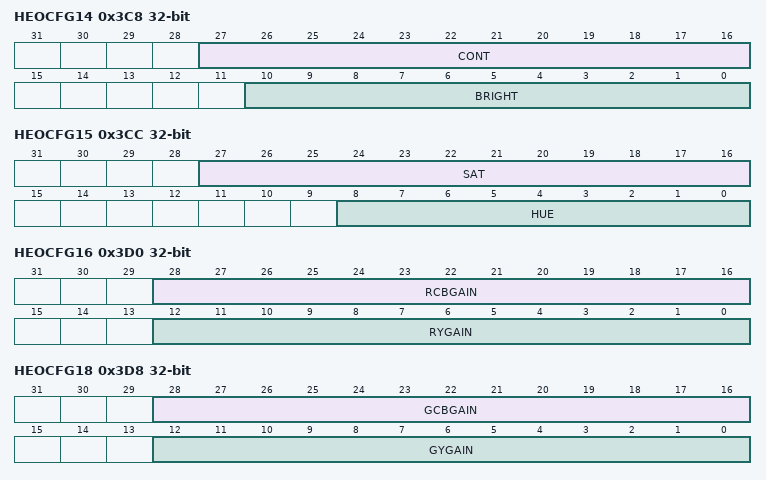
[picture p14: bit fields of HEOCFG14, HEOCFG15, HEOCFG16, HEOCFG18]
0x3C8 HEOCFG14 — High-End Overlay Configuration Register 14
  [27:16] CONT — Contrast Value
  [10:0] BRIGHT — Brightness Value
0x3CC HEOCFG15 — High-End Overlay Configuration Register 15
  [27:16] SAT — Saturation Value
  [8:0] HUE — Hue Value in Degrees
0x3D0 HEOCFG16 — High-End Overlay Configuration Register 16
  [28:16] RCBGAIN — Color Space Conversion CB Coefficient for Red Component 1:2:10 Format
  [12:0] RYGAIN — Color Space Conversion Y Coefficient for Red Component 1:2:10 Format
0x3D4 HEOCFG17 — High-End Overlay Configuration Register 17
  [12:0] RCRGAIN — Color Space Conversion CR Coefficient for Red Component 1:2:10 Format
0x3D8 HEOCFG18 — High-End Overlay Configuration Register 18
  [28:16] GCBGAIN — Color Space Conversion CB Coefficient for Green Component 1:2:10 Format
  [12:0] GYGAIN — Color Space Conversion Y Coefficient for Green Component 1:2:10 Format
0x3DC HEOCFG19 — High-End Overlay Configuration Register 19
  [12:0] GCRGAIN — Color Space Conversion CR Coefficient for Green Component 1:2:10 Format
0x3E0 HEOCFG20 — High-End Overlay Configuration Register 20
  [28:16] BCBGAIN — Color Space Conversion CB Coefficient for Blue Component 1:2:10 Format
  [12:0] BYGAIN — Color Space Conversion Y Coefficient for Blue Component 1:2:10 Format
0x3E4 HEOCFG21 — High-End Overlay Configuration Register 21
  [12:0] BCRGAIN — Color Space Conversion Y Coefficient for Blue Component 1:2:10 Format
0x3E8 HEOCFG22 — High-End Overlay Configuration Register 22
  [2] CROFF — Red Chroma Offset
  [1] CBOFF — Blue Chroma Offset
  [0] YOFF — Luma Offset
0x3EC HEOCFG23 — High-End Overlay Configuration Register 23
  [5] HXSCEN — Horizontal Scaler Chroma Component Enable
  [4] HXSYEN — Horizontal Scaler Luma Component Enable
  [1] VXSCEN — Vertical Scaler Chroma Component Enable
  [0] VXSYEN — Vertical Scaler Luma Component Enable
0x3F0 HEOCFG24 — High-End Overlay Configuration Register 24
  [23:0] VXSYFACT — Vertical Luma Scaling Factor
0x3F4 HEOCFG25 — High-End Overlay Configuration Register 25
  [23:0] VXSCFACT — Vertical Chroma Scaling Factor
0x3F8 HEOCFG26 — High-End Overlay Configuration Register 26
  [23:0] HXSYFACT — Horizontal Luma Scaling factor
0x3FC HEOCFG27 — High-End Overlay Configuration Register 27
  [23:0] HXSCFACT — Horizontal Chroma Scaling Factor
0x400 HEOCFG28 — High-End Overlay Configuration Register 28
  [27:24] VXSCOFF1 — Vertical Scaler Chroma Default Phase for Field 1
  [19:16] VXSCOFF — Vertical Scaler Chroma Default Phase for Field 0 or Progressive Scan
  [11:8] VXSYOFF1 — Vertical Scaler Luma Default Phase for Field 1
  [3:0] VXSYOFF — Vertical Scaler Luma Default Phase for Field 0 or Progressive Scan
0x404 HEOCFG29 — High-End Overlay Configuration Register 29
  [19:16] HXSCOFF — Hozontal Scaler Chroma Offset
  [3:0] HXSYOFF — Horizontal Scaler Luma Offset
0x408 HEOCFG30 — High-End Overlay Configuration Register 30
  [25:24] VXSCCFG1 — Vertical Scaler Chroma Configuration for Field 1(only used for YCrCb Interlaced Frame Content)
  [22] VXSCBICU — Vertical Scaler Predefined Bicubic Taps Selected for Chroma/GB Component
    0=Bicubic taps values are not selected; 1=Bicubic taps values are selected
  [21] VXSC1201N — Vertical Scaler Bilinear 2 Taps Position among 4 Taps Filter for Chroma/GB Component
    0=When selected, bilinear taps values are located on 0 and 1 positions (left aligned); 1=When selected, bilinear taps values are located on 0 and 1 positions (center aligned)
  [20] VXSCTAP2 — Vertical Scaler Predefined Bilinear 2 Taps Selected for Chroma/GB Component
    0=Bilinear 2 taps value not selected; 1=Bilinear 2 taps value selected
  [17:16] VXSCCFG — Vertical Scaler Chroma/GB Configuration for Field 0 or Progressive Scan
  [9:8] VXSYCFG1 — Vertical Scaler Chroma/GB Configuration for Field 1 (only used for interlaced frame content)
  [6] VXSYBICU — Vertical Scaler Predefined Bicubic Taps Selected for Luma/AR Component
    values as VXSCBICU
  [5] VXSY1201N — Vertical Scaler Bilinear 2 Taps Position among 4 Filter Taps for Luma/AR Component
    0=When selected, bilinear tap values are located on 0 and 1 positions (left-aligned); 1=When selected, bilinear tap values are located on 0 and 1 positions (center-aligned)
  [4] VXSYTAP2 — Vertical Scaler Predefined Bilinear 2 Taps Selected for Luma/AR Component
    values as VXSCTAP2
  [1:0] VXSYCFG — Vertical Scaler Luma/AR Configuration for Field 0 or Progressive Scan
0x40C HEOCFG31 — High-End Overlay Configuration Register 31
  [21] HXSCBICU — Horizontal Scaler Bicubic Coefficients Selected for Chroma Component
    values as HEOCFG30.VXSCBICU
  [20] HXSCTAP2 — Horizontal Scaler Predefined Bilinear 2 Taps Selected for Chroma Component
    values as HEOCFG30.VXSCTAP2
  [17:16] HXSCCFG — Horizontal Scaler Chroma/GB Configuration
  [5] HXSYBICU — Horizontal Scaler Predefined Bicubic Taps Selected for Luma/AR Component
    values as HEOCFG30.VXSCBICU
  [4] HXSYTAP2 — Horizontal Scaler Predefined Bilinear 2 Taps Selected for Luma/AR Component
    values as HEOCFG30.VXSCTAP2
  [1:0] HXSYCFG — Horizontal Scaler Luma Configuration
{0x410+8i} LCDC_HEOVTAP[{i}] (i=0..15) group
  0x00 HEOVTAP10P — High-End Overlay VXS T10 Phi Register
    [28:16] TAP1 — Vertical Filter Tap 1 Coefficient
    [12:0] TAP0 — Vertical Filter Tap 0 Coefficient
  0x04 HEOVTAP32P — High-End Overlay VXS T32 Phi Register
    [28:16] TAP3 — Vertical Filter Tap 3 Coefficient
    [12:0] TAP2 — Vertical Filter Tap 2 Coefficient
{0x490+8i} LCDC_HEOHTAP[{i}] (i=0..15) group
  0x00 HEOHTAP10P — High-End Overlay HXS T10 Phi Register
    [28:16] TAP1 — Horitzontal Filter Tap 1 Coefficient
    [12:0] TAP0 — Horizontal Filter Tap 0 Coefficient
  0x04 HEOHTAP32P — High-End Overlay HXS T32 Phi Register
    [28:16] TAP3 — Horizontal Filter Tap 3 Coefficient
    [12:0] TAP2 — Horizontal Filter Tap 2 Coefficient
{0x700+4i} BASECLUT[{i}] (i=0..255) — Base Layer CLUT Register x
  [31:24] ACLUT — Alpha Component Entry
  [23:16] RCLUT — Red Color Entry
  [15:8] GCLUT — Green Color Entry
  [7:0] BCLUT — Blue Color Entry
{0xB00+4i} OVR1CLUT[{i}] (i=0..255) — Overlay 1 CLUT Register x
  [31:24] ACLUT — Alpha Color Entry
  [23:16] RCLUT — Red Color Entry
  [15:8] GCLUT — Green Color Entry
  [7:0] BCLUT — Blue Color Entry
{0x1300+4i} HEOCLUT[{i}] (i=0..255) — High-End Overlay CLUT Register x
  fields as OVR1CLUT[0]
